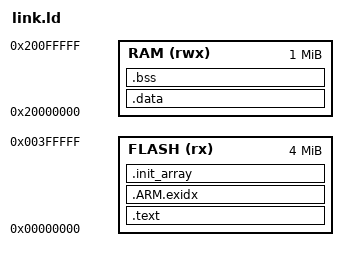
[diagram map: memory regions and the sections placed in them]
MEMORY { FLASH (rx) : ORIGIN = 0x00000000, LENGTH = 4M
         RAM (rwx)  : ORIGIN = 0x20000000, LENGTH = 1M }
ENTRY(Reset_Handler)
SECTIONS {
  .text : { KEEP(*(.vectors)) *(.text*) *(.rodata*) . = ALIGN(4); } > FLASH
  .ARM.exidx : { *(.ARM.exidx*) } > FLASH
  .init_array : { __init_array_start = .; KEEP(*(.init_array*)) __init_array_end = .; } > FLASH
  _sidata = .;
  .data : AT(_sidata) { _sdata = .; *(.data*) . = ALIGN(4); _edata = .; } > RAM
  .bss : { _sbss = .; *(.bss*) *(COMMON) . = ALIGN(4); _ebss = .; } > RAM
  _estack = ORIGIN(RAM) + LENGTH(RAM);
  end = _ebss; _end = _ebss;
}
